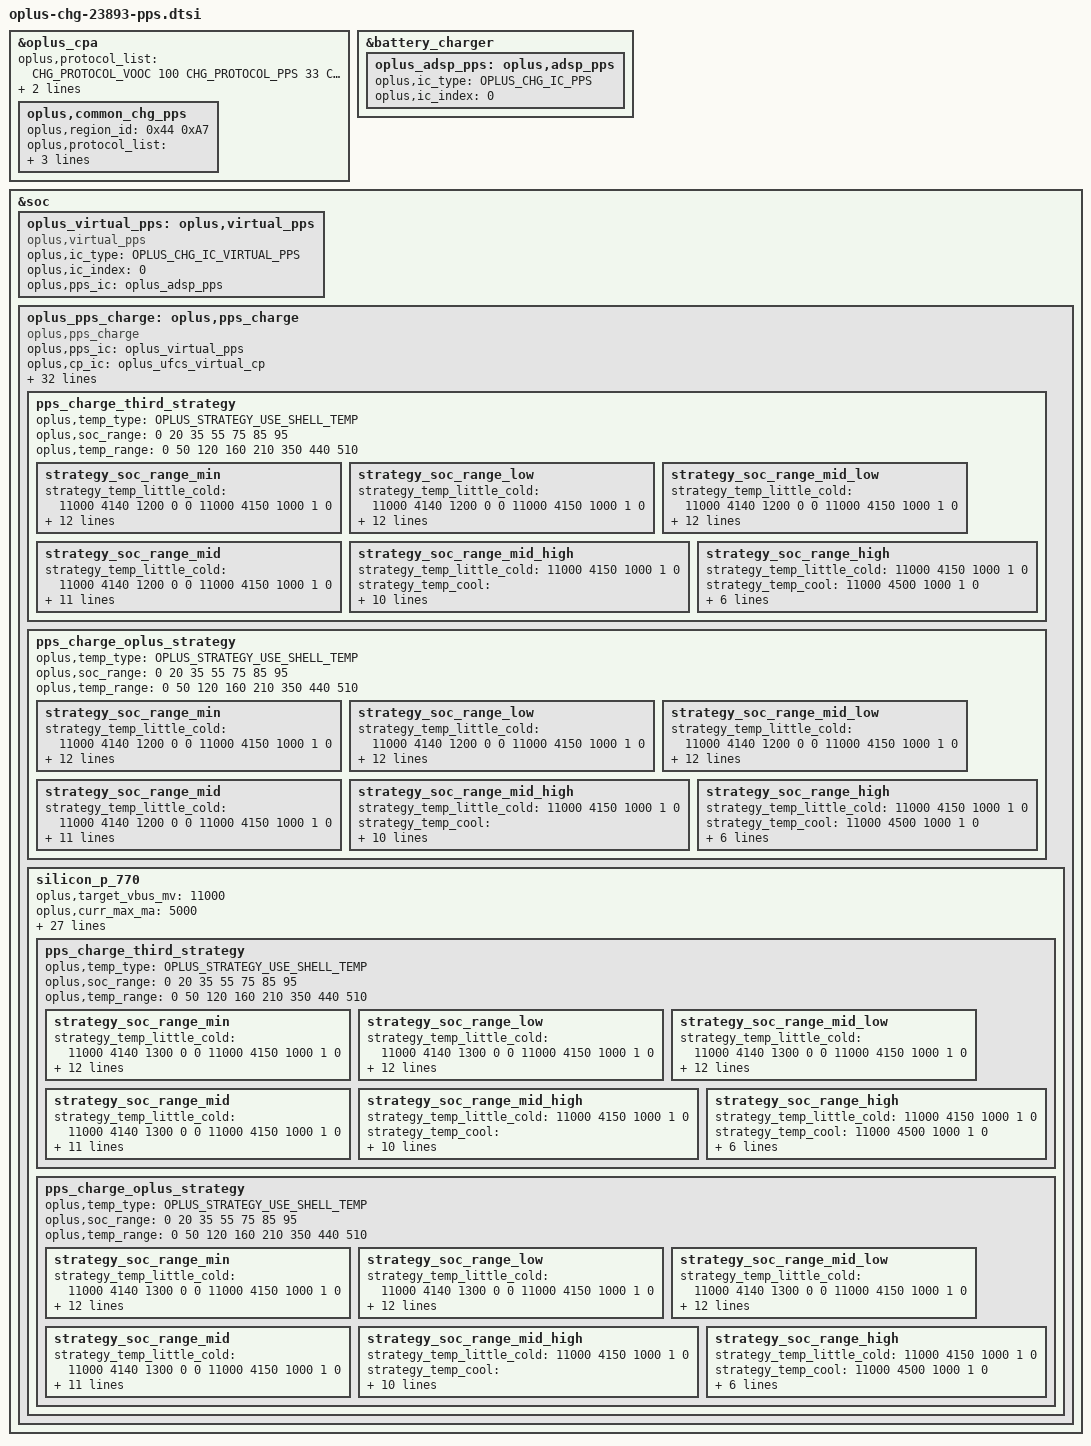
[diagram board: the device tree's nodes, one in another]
&oplus_cpa {
	oplus,protocol_list = <CHG_PROTOCOL_VOOC 100
				   CHG_PROTOCOL_PPS  33
				   CHG_PROTOCOL_PD   18
				   CHG_PROTOCOL_QC   18>;
	oplus,default_protocol_list = <CHG_PROTOCOL_PD
					   CHG_PROTOCOL_PPS
					   CHG_PROTOCOL_VOOC>;
	oplus,common_chg_pps {
		oplus,region_id = /bits/ 8 <0x44 0xA7>;
		oplus,protocol_list = <CHG_PROTOCOL_VOOC 100
				   CHG_PROTOCOL_PPS  55
				   CHG_PROTOCOL_PD   18
				   CHG_PROTOCOL_QC   18>;
		oplus,default_protocol_list = <CHG_PROTOCOL_PD
					   CHG_PROTOCOL_PPS
					   CHG_PROTOCOL_VOOC>;
	};
};
&battery_charger {
	oplus_adsp_pps: oplus,adsp_pps {
		oplus,ic_type = <OPLUS_CHG_IC_PPS>;
		oplus,ic_index = <0>;
	};
};
&soc {
	oplus_virtual_pps: oplus,virtual_pps {
		compatible = "oplus,virtual_pps";

		oplus,ic_type = <OPLUS_CHG_IC_VIRTUAL_PPS>;
		oplus,ic_index = <0>;
		oplus,pps_ic = <&oplus_adsp_pps>;
	};
	oplus_pps_charge: oplus,pps_charge {
		compatible = "oplus,pps_charge";
		oplus,pps_ic = <&oplus_virtual_pps>;
		oplus,cp_ic = <&oplus_ufcs_virtual_cp>;
		oplus,dpdm_switch_ic = <&oplus_adsp_dpdm_switch>;

		oplus,target_vbus_mv = <11000>;
		oplus,curr_max_ma = <5000>;

		oplus,pps_warm_allow_vol = <4000>;
		oplus,pps_warm_allow_soc = <55>;
		oplus,pps_strategy_normal_current = <5000>;
		oplus,pps_over_high_or_low_current = <3000>;
		oplus,pps_timeout_third = <13937>;
		oplus,pps_timeout_oplus = <13937>;
		oplus,pps_ibat_over_third = <6400>;
		oplus,pps_ibat_over_oplus = <6400>;
		oplus,pps_full_cool_sw_vbat = <4500>;
		oplus,pps_full_normal_sw_vbat = <4500>;
		oplus,pps_full_normal_hw_vbat = <4540>;
		oplus,pps_full_ffc_vbat = <4550>;
		oplus,pps_full_warm_vbat = <4130>;
		oplus,pps_full_cool_sw_vbat_third = <4500>;
		oplus,pps_full_normal_sw_vbat_third= <4500>;
		oplus,pps_full_normal_hw_vbat_third = <4540>;
		oplus,pps_current_change_timeout = <100>;
		oplus,pps_strategy_batt_high_temp = <410 420 430 400 410 420>;
		oplus,pps_strategy_high_current = <5000 5000 3000 5000 5000 5000>;
		oplus,pps_little_cool_high_temp = <210>;
		oplus,curve_strategy_name = "pps_ufcs_curve_v2";
		oplus,pps_charge_strategy_soc = <0 20 35 55 75 85 95>;
		oplus,pps_charge_strategy_temp = <0 50 120 160 350 440 510>;

		oplus,plc_strategy-data = <&pps_simple_strategy>;
		oplus,plc_strategy-names = "default";

		pps_charge_third_strategy {
			oplus,temp_type = <OPLUS_STRATEGY_USE_SHELL_TEMP>;
			oplus,soc_range = <0 20 35 55 75 85 95>;
			oplus,temp_range = <0 50 120 160 210 350 440 510>;

			strategy_soc_range_min {
				strategy_temp_little_cold =	<11000 4140 1200 0 0
								11000 4150 1000 1 0>;
				strategy_temp_cool =		<11000 4150 2000 0 0
								11000 4150 1500 0 0
								11000 4490 1200 0 0
								11000 4500 1000 1 0>;
				strategy_temp_little_cool =	<11000 4150 2600 0 0
								11000 4150 2500 0 0
								11000 4330 2000 0 0
								11000 4330 1500 0 0
								11000 4490 1200 0 0
								11000 4500 1000 1 0>;
				strategy_temp_little_cool_high = <11000 4200 5000 0 0
								11000 4200 4500 0 0
								11000 4200 4000 0 0
								11000 4330 3900 0 0
								11000 4330 3500 0 0
								11000 4490 3100 0 0
								11000 4490 3000 0 0
								11000 4490 2600 0 0
								11000 4490 2500 0 0
								11000 4490 2000 0 0
								11000 4490 1500 0 0
								11000 4500 1000 1 0>;
				strategy_temp_normal_low =	<11000 4480 5000 0 0
								11000 4480 4500 0 0
								11000 4480 4000 0 0
								11000 4490 3900 0 0
								11000 4490 3500 0 0
								11000 4490 3100 0 0
								11000 4490 3000 0 0
								11000 4490 2500 0 0
								11000 4490 2000 0 0
								11000 4490 1500 0 0
								11000 4500 1000 1 0>;
				strategy_temp_normal_high =	<11000 4465 5000 0 0
								11000 4465 4500 0 0
								11000 4465 4000 0 0
								11000 4465 3900 0 0
								11000 4465 3500 0 0
								11000 4465 3100 0 0
								11000 4465 3000 0 0
								11000 4465 2500 0 0
								11000 4465 2000 0 0
								11000 4465 1500 0 0
								11000 4475 1000 1 0>;
				strategy_temp_warm =		<11000 4120 1400 0 0
								11000 4130 1000 1 0>;
			};
			strategy_soc_range_low {
				strategy_temp_little_cold =	<11000 4140 1200 0 0
								11000 4150 1000 1 0>;
				strategy_temp_cool =		<11000 4150 2000 0 0
								11000 4150 1500 0 0
								11000 4490 1200 0 0
								11000 4500 1000 1 0>;
				strategy_temp_little_cool =	<11000 4150 2600 0 0
								11000 4150 2500 0 0
								11000 4330 2000 0 0
								11000 4330 1500 0 0
								11000 4490 1200 0 0
								11000 4500 1000 1 0>;
				strategy_temp_little_cool_high = <11000 4200 5000 0 0
								11000 4200 4500 0 0
								11000 4200 4000 0 0
								11000 4330 3900 0 0
								11000 4330 3500 0 0
								11000 4490 3100 0 0
								11000 4490 3000 0 0
								11000 4490 2600 0 0
								11000 4490 2500 0 0
								11000 4490 2000 0 0
								11000 4490 1500 0 0
								11000 4500 1000 1 0>;
				strategy_temp_normal_low =	<11000 4480 5000 0 0
								11000 4480 4500 0 0
								11000 4480 4000 0 0
								11000 4490 3900 0 0
								11000 4490 3500 0 0
								11000 4490 3100 0 0
								11000 4490 3000 0 0
								11000 4490 2500 0 0
								11000 4490 2000 0 0
								11000 4490 1500 0 0
								11000 4500 1000 1 0>;
				strategy_temp_normal_high =	<11000 4465 5000 0 0
								11000 4465 4500 0 0
								11000 4465 4000 0 0
								11000 4465 3900 0 0
								11000 4465 3500 0 0
								11000 4465 3100 0 0
								11000 4465 3000 0 0
								11000 4465 2500 0 0
								11000 4465 2000 0 0
								11000 4465 1500 0 0
								11000 4475 1000 1 0>;
				strategy_temp_warm =		<11000 4120 1400 0 0
								11000 4130 1000 1 0>;
			};
			strategy_soc_range_mid_low {
				strategy_temp_little_cold =	<11000 4140 1200 0 0
								11000 4150 1000 1 0>;
				strategy_temp_cool =		<11000 4150 2000 0 0
								11000 4150 1500 0 0
								11000 4490 1200 0 0
								11000 4500 1000 1 0>;
				strategy_temp_little_cool =	<11000 4150 2600 0 0
								11000 4150 2500 0 0
								11000 4330 2000 0 0
								11000 4330 1500 0 0
								11000 4490 1200 0 0
								11000 4500 1000 1 0>;
				strategy_temp_little_cool_high = <11000 4200 5000 0 0
								11000 4200 4500 0 0
								11000 4200 4000 0 0
								11000 4330 3900 0 0
								11000 4330 3500 0 0
								11000 4490 3100 0 0
								11000 4490 3000 0 0
								11000 4490 2600 0 0
								11000 4490 2500 0 0
								11000 4490 2000 0 0
								11000 4490 1500 0 0
								11000 4500 1000 1 0>;
				strategy_temp_normal_low =	<11000 4480 5000 0 0
								11000 4480 4500 0 0
								11000 4480 4000 0 0
								11000 4490 3900 0 0
								11000 4490 3500 0 0
								11000 4490 3100 0 0
								11000 4490 3000 0 0
								11000 4490 2500 0 0
								11000 4490 2000 0 0
								11000 4490 1500 0 0
								11000 4500 1000 1 0>;
				strategy_temp_normal_high =	<11000 4465 5000 0 0
								11000 4465 4500 0 0
								11000 4465 4000 0 0
								11000 4465 3900 0 0
								11000 4465 3500 0 0
								11000 4465 3100 0 0
								11000 4465 3000 0 0
								11000 4465 2500 0 0
								11000 4465 2000 0 0
								11000 4465 1500 0 0
								11000 4475 1000 1 0>;
				strategy_temp_warm =		<11000 4120 1400 0 0
								11000 4130 1000 1 0>;
			};
			strategy_soc_range_mid {
				strategy_temp_little_cold =	<11000 4140 1200 0 0
								11000 4150 1000 1 0>;
				strategy_temp_cool =		<11000 4150 2000 0 0
								11000 4150 1500 0 0
								11000 4490 1200 0 0
								11000 4500 1000 1 0>;
				strategy_temp_little_cool =	<11000 4150 2600 0 0
								11000 4150 2500 0 0
								11000 4330 2000 0 0
								11000 4330 1500 0 0
								11000 4490 1200 0 0
								11000 4500 1000 1 0>;
				strategy_temp_little_cool_high = <11000 4490 3000 0 0
								11000 4490 2600 0 0
								11000 4490 2500 0 0
								11000 4490 2000 0 0
								11000 4490 1500 0 0
								11000 4500 1000 1 0>;
				strategy_temp_normal_low =	<11000 4490 3500 0 0
								11000 4490 3100 0 0
								11000 4490 3000 0 0
								11000 4490 2500 0 0
								11000 4490 2000 0 0
								11000 4490 1500 0 0
								11000 4500 1000 1 0>;
				strategy_temp_normal_high =	<11000 4465 4000 0 0
								11000 4465 3900 0 0
								11000 4465 3500 0 0
								11000 4465 3100 0 0
								11000 4465 3000 0 0
								11000 4465 2500 0 0
								11000 4465 2000 0 0
								11000 4465 1500 0 0
								11000 4475 1000 1 0>;
				strategy_temp_warm =		<11000 4130 1000 1 0>;
			};
			strategy_soc_range_mid_high {
				strategy_temp_little_cold =	<11000 4150 1000 1 0>;
				strategy_temp_cool =		<11000 4150 1500 0 0
								11000 4490 1200 0 0
								11000 4500 1000 1 0>;
				strategy_temp_little_cool =	<11000 4330 2000 0 0
								11000 4330 1500 0 0
								11000 4490 1200 0 0
								11000 4500 1000 1 0>;
				strategy_temp_little_cool_high = <11000 4490 2000 0 0
								11000 4490 1500 0 0
								11000 4500 1000 1 0>;
				strategy_temp_normal_low =	<11000 4490 2500 0 0
								11000 4490 2000 0 0
								11000 4490 1500 0 0
								11000 4500 1000 1 0>;
				strategy_temp_normal_high =	<11000 4465 2500 0 0
								11000 4465 2000 0 0
								11000 4465 1500 0 0
								11000 4475 1000 1 0>;
				strategy_temp_warm =		<11000 4130 1000 1 0>;
			};
			strategy_soc_range_high {
				strategy_temp_little_cold =	<11000 4150 1000 1 0>;
				strategy_temp_cool =		<11000 4500 1000 1 0>;
				strategy_temp_little_cool =	<11000 4500 1000 1 0>;
				strategy_temp_little_cool_high = <11000 4500 1000 1 0>;
				strategy_temp_normal_low =	<11000 4500 1000 1 0>;
				strategy_temp_normal_high =	<11000 4475 1000 1 0>;
				strategy_temp_warm =		<11000 4130 1000 1 0>;
			};
		};

		pps_charge_oplus_strategy {
			oplus,temp_type = <OPLUS_STRATEGY_USE_SHELL_TEMP>;
			oplus,soc_range = <0 20 35 55 75 85 95>;
			oplus,temp_range = <0 50 120 160 210 350 440 510>;

			strategy_soc_range_min {
				strategy_temp_little_cold =	<11000 4140 1200 0 0
								11000 4150 1000 1 0>;
				strategy_temp_cool =		<11000 4150 2000 0 0
								11000 4150 1500 0 0
								11000 4490 1200 0 0
								11000 4500 1000 1 0>;
				strategy_temp_little_cool =	<11000 4150 2600 0 0
								11000 4150 2500 0 0
								11000 4330 2000 0 0
								11000 4330 1500 0 0
								11000 4490 1200 0 0
								11000 4500 1000 1 0>;
				strategy_temp_little_cool_high = <11000 4200 5000 0 0
								11000 4200 4500 0 0
								11000 4200 4000 0 0
								11000 4330 3900 0 0
								11000 4330 3500 0 0
								11000 4490 3100 0 0
								11000 4490 3000 0 0
								11000 4490 2600 0 0
								11000 4490 2500 0 0
								11000 4490 2000 0 0
								11000 4490 1500 0 0
								11000 4500 1000 1 0>;
				strategy_temp_normal_low =	<11000 4480 5000 0 0
								11000 4480 4500 0 0
								11000 4480 4000 0 0
								11000 4490 3900 0 0
								11000 4490 3500 0 0
								11000 4490 3100 0 0
								11000 4490 3000 0 0
								11000 4490 2500 0 0
								11000 4490 2000 0 0
								11000 4490 1500 0 0
								11000 4500 1000 1 0>;
				strategy_temp_normal_high =	<11000 4465 5000 0 0
								11000 4465 4500 0 0
								11000 4465 4000 0 0
								11000 4465 3900 0 0
								11000 4465 3500 0 0
								11000 4465 3100 0 0
								11000 4465 3000 0 0
								11000 4465 2500 0 0
								11000 4465 2000 0 0
								11000 4465 1500 0 0
								11000 4475 1000 1 0>;
				strategy_temp_warm =		<11000 4120 1400 0 0
								11000 4130 1000 1 0>;
			};
			strategy_soc_range_low {
				strategy_temp_little_cold =	<11000 4140 1200 0 0
								11000 4150 1000 1 0>;
				strategy_temp_cool =		<11000 4150 2000 0 0
								11000 4150 1500 0 0
								11000 4490 1200 0 0
								11000 4500 1000 1 0>;
				strategy_temp_little_cool =	<11000 4150 2600 0 0
								11000 4150 2500 0 0
								11000 4330 2000 0 0
								11000 4330 1500 0 0
								11000 4490 1200 0 0
								11000 4500 1000 1 0>;
				strategy_temp_little_cool_high = <11000 4200 5000 0 0
								11000 4200 4500 0 0
								11000 4200 4000 0 0
								11000 4330 3900 0 0
								11000 4330 3500 0 0
								11000 4490 3100 0 0
								11000 4490 3000 0 0
								11000 4490 2600 0 0
								11000 4490 2500 0 0
								11000 4490 2000 0 0
								11000 4490 1500 0 0
								11000 4500 1000 1 0>;
				strategy_temp_normal_low =	<11000 4480 5000 0 0
								11000 4480 4500 0 0
								11000 4480 4000 0 0
								11000 4490 3900 0 0
								11000 4490 3500 0 0
								11000 4490 3100 0 0
								11000 4490 3000 0 0
								11000 4490 2500 0 0
								11000 4490 2000 0 0
								11000 4490 1500 0 0
								11000 4500 1000 1 0>;
				strategy_temp_normal_high =	<11000 4465 5000 0 0
								11000 4465 4500 0 0
								11000 4465 4000 0 0
								11000 4465 3900 0 0
								11000 4465 3500 0 0
								11000 4465 3100 0 0
								11000 4465 3000 0 0
								11000 4465 2500 0 0
								11000 4465 2000 0 0
								11000 4465 1500 0 0
								11000 4475 1000 1 0>;
				strategy_temp_warm =		<11000 4120 1400 0 0
								11000 4130 1000 1 0>;
			};
			strategy_soc_range_mid_low {
				strategy_temp_little_cold =	<11000 4140 1200 0 0
								11000 4150 1000 1 0>;
				strategy_temp_cool =		<11000 4150 2000 0 0
								11000 4150 1500 0 0
								11000 4490 1200 0 0
								11000 4500 1000 1 0>;
				strategy_temp_little_cool =	<11000 4150 2600 0 0
								11000 4150 2500 0 0
								11000 4330 2000 0 0
								11000 4330 1500 0 0
								11000 4490 1200 0 0
								11000 4500 1000 1 0>;
				strategy_temp_little_cool_high = <11000 4200 5000 0 0
								11000 4200 4500 0 0
								11000 4200 4000 0 0
								11000 4330 3900 0 0
								11000 4330 3500 0 0
								11000 4490 3100 0 0
								11000 4490 3000 0 0
								11000 4490 2600 0 0
								11000 4490 2500 0 0
								11000 4490 2000 0 0
								11000 4490 1500 0 0
								11000 4500 1000 1 0>;
				strategy_temp_normal_low =	<11000 4480 5000 0 0
								11000 4480 4500 0 0
								11000 4480 4000 0 0
								11000 4490 3900 0 0
								11000 4490 3500 0 0
								11000 4490 3100 0 0
								11000 4490 3000 0 0
								11000 4490 2500 0 0
								11000 4490 2000 0 0
								11000 4490 1500 0 0
								11000 4500 1000 1 0>;
				strategy_temp_normal_high =	<11000 4465 5000 0 0
								11000 4465 4500 0 0
								11000 4465 4000 0 0
								11000 4465 3900 0 0
								11000 4465 3500 0 0
								11000 4465 3100 0 0
								11000 4465 3000 0 0
								11000 4465 2500 0 0
								11000 4465 2000 0 0
								11000 4465 1500 0 0
								11000 4475 1000 1 0>;
				strategy_temp_warm =		<11000 4120 1400 0 0
								11000 4130 1000 1 0>;
			};
			strategy_soc_range_mid {
				strategy_temp_little_cold =	<11000 4140 1200 0 0
								11000 4150 1000 1 0>;
				strategy_temp_cool =		<11000 4150 2000 0 0
								11000 4150 1500 0 0
								11000 4490 1200 0 0
								11000 4500 1000 1 0>;
				strategy_temp_little_cool =	<11000 4150 2600 0 0
								11000 4150 2500 0 0
								11000 4330 2000 0 0
								11000 4330 1500 0 0
								11000 4490 1200 0 0
								11000 4500 1000 1 0>;
				strategy_temp_little_cool_high = <11000 4490 3000 0 0
								11000 4490 2600 0 0
								11000 4490 2500 0 0
								11000 4490 2000 0 0
								11000 4490 1500 0 0
								11000 4500 1000 1 0>;
				strategy_temp_normal_low =	<11000 4490 3500 0 0
								11000 4490 3100 0 0
								11000 4490 3000 0 0
								11000 4490 2500 0 0
								11000 4490 2000 0 0
								11000 4490 1500 0 0
								11000 4500 1000 1 0>;
				strategy_temp_normal_high =	<11000 4465 4000 0 0
								11000 4465 3900 0 0
								11000 4465 3500 0 0
								11000 4465 3100 0 0
								11000 4465 3000 0 0
								11000 4465 2500 0 0
								11000 4465 2000 0 0
								11000 4465 1500 0 0
								11000 4475 1000 1 0>;
				strategy_temp_warm =		<11000 4130 1000 1 0>;
			};
			strategy_soc_range_mid_high {
				strategy_temp_little_cold =	<11000 4150 1000 1 0>;
				strategy_temp_cool =		<11000 4150 1500 0 0
								11000 4490 1200 0 0
								11000 4500 1000 1 0>;
				strategy_temp_little_cool =	<11000 4330 2000 0 0
								11000 4330 1500 0 0
								11000 4490 1200 0 0
								11000 4500 1000 1 0>;
				strategy_temp_little_cool_high = <11000 4490 2000 0 0
								11000 4490 1500 0 0
								11000 4500 1000 1 0>;
				strategy_temp_normal_low =	<11000 4490 2500 0 0
								11000 4490 2000 0 0
								11000 4490 1500 0 0
								11000 4500 1000 1 0>;
				strategy_temp_normal_high =	<11000 4465 2500 0 0
								11000 4465 2000 0 0
								11000 4465 1500 0 0
								11000 4475 1000 1 0>;
				strategy_temp_warm =		<11000 4130 1000 1 0>;
			};
			strategy_soc_range_high {
				strategy_temp_little_cold =	<11000 4150 1000 1 0>;
				strategy_temp_cool =		<11000 4500 1000 1 0>;
				strategy_temp_little_cool =	<11000 4500 1000 1 0>;
				strategy_temp_little_cool_high = <11000 4500 1000 1 0>;
				strategy_temp_normal_low =	<11000 4500 1000 1 0>;
				strategy_temp_normal_high =	<11000 4475 1000 1 0>;
				strategy_temp_warm =		<11000 4130 1000 1 0>;
			};
		};

		silicon_p_770 {
			oplus,target_vbus_mv = <11000>;
			oplus,curr_max_ma = <5000>;

			oplus,pps_warm_allow_vol = <4000>;
			oplus,pps_warm_allow_soc = <55>;
			oplus,pps_strategy_normal_current = <5000>;
			oplus,pps_over_high_or_low_current = <3000>;
			oplus,pps_timeout_third = <14425>;
			oplus,pps_timeout_oplus = <14425>;
			oplus,pps_ibat_over_third = <6400>;
			oplus,pps_ibat_over_oplus = <6400>;
			oplus,pps_full_cool_sw_vbat = <4500>;
			oplus,pps_full_normal_sw_vbat = <4500>;
			oplus,pps_full_normal_hw_vbat = <4540>;
			oplus,pps_full_ffc_vbat = <4550>;
			oplus,pps_full_warm_vbat = <4130>;
			oplus,pps_full_cool_sw_vbat_third = <4500>;
			oplus,pps_full_normal_sw_vbat_third= <4500>;
			oplus,pps_full_normal_hw_vbat_third = <4540>;
			oplus,pps_current_change_timeout = <100>;
			oplus,pps_strategy_batt_high_temp = <410 420 430 400 410 420>;
			oplus,pps_strategy_high_current = <5000 5000 3000 5000 5000 5000>;
			oplus,pps_little_cool_high_temp = <210>;
			oplus,curve_strategy_name = "pps_ufcs_curve_v2";
			oplus,pps_charge_strategy_soc = <0 20 35 55 75 85 95>;
			oplus,pps_charge_strategy_temp = <0 50 120 160 350 440 510>;

			pps_charge_third_strategy {
				oplus,temp_type = <OPLUS_STRATEGY_USE_SHELL_TEMP>;
				oplus,soc_range = <0 20 35 55 75 85 95>;
				oplus,temp_range = <0 50 120 160 210 350 440 510>;

				strategy_soc_range_min {
					strategy_temp_little_cold =	<11000 4140 1300 0 0
									11000 4150 1000 1 0>;
					strategy_temp_cool =		<11000 4150 2100 0 0
									11000 4150 2000 0 0
									11000 4150 1500 0 0
									11000 4490 1300 0 0
									11000 4500 1000 1 0>;
					strategy_temp_little_cool =	<11000 4150 2700 0 0
									11000 4150 2500 0 0
									11000 4330 2100 0 0
									11000 4330 2000 0 0
									11000 4330 1500 0 0
									11000 4490 1300 0 0
									11000 4500 1000 1 0>;
					strategy_temp_little_cool_high = <11000 4150 5000 0 0
									11000 4150 4500 0 0
									11000 4280 4000 0 0
									11000 4280 3500 0 0
									11000 4490 3200 0 0
									11000 4490 3000 0 0
									11000 4490 2700 0 0
									11000 4490 2500 0 0
									11000 4490 2000 0 0
									11000 4490 1500 0 0
									11000 4500 1000 1 0>;
					strategy_temp_normal_low =	<11000 4470 5000 0 0
									11000 4470 4500 0 0
									11000 4470 4000 0 0
									11000 4490 3800 0 0
									11000 4490 3500 0 0
									11000 4490 3000 0 0
									11000 4490 2500 0 0
									11000 4490 2000 0 0
									11000 4490 1500 0 0
									11000 4500 1000 1 0>;
					strategy_temp_normal_high =	<11000 4470 5000 0 0
									11000 4470 4500 0 0
									11000 4470 4000 0 0
									11000 4465 3800 0 0
									11000 4465 3500 0 0
									11000 4465 3000 0 0
									11000 4465 2500 0 0
									11000 4465 2000 0 0
									11000 4465 1500 0 0
									11000 4475 1000 1 0>;
					strategy_temp_warm =		<11000 4120 1500 0 0
									11000 4130 1000 1 0>;
				};
				strategy_soc_range_low {
					strategy_temp_little_cold =	<11000 4140 1300 0 0
									11000 4150 1000 1 0>;
					strategy_temp_cool =		<11000 4150 2100 0 0
									11000 4150 2000 0 0
									11000 4150 1500 0 0
									11000 4490 1300 0 0
									11000 4500 1000 1 0>;
					strategy_temp_little_cool =	<11000 4150 2700 0 0
									11000 4150 2500 0 0
									11000 4330 2100 0 0
									11000 4330 2000 0 0
									11000 4330 1500 0 0
									11000 4490 1300 0 0
									11000 4500 1000 1 0>;
					strategy_temp_little_cool_high = <11000 4150 5000 0 0
									11000 4150 4500 0 0
									11000 4280 4000 0 0
									11000 4280 3500 0 0
									11000 4490 3200 0 0
									11000 4490 3000 0 0
									11000 4490 2700 0 0
									11000 4490 2500 0 0
									11000 4490 2000 0 0
									11000 4490 1500 0 0
									11000 4500 1000 1 0>;
					strategy_temp_normal_low =	<11000 4470 5000 0 0
									11000 4470 4500 0 0
									11000 4470 4000 0 0
									11000 4490 3800 0 0
									11000 4490 3500 0 0
									11000 4490 3000 0 0
									11000 4490 2500 0 0
									11000 4490 2000 0 0
									11000 4490 1500 0 0
									11000 4500 1000 1 0>;
					strategy_temp_normal_high =	<11000 4470 5000 0 0
									11000 4470 4500 0 0
									11000 4470 4000 0 0
									11000 4465 3800 0 0
									11000 4465 3500 0 0
									11000 4465 3000 0 0
									11000 4465 2500 0 0
									11000 4465 2000 0 0
									11000 4465 1500 0 0
									11000 4475 1000 1 0>;
					strategy_temp_warm =		<11000 4120 1500 0 0
									11000 4130 1000 1 0>;
				};
				strategy_soc_range_mid_low {
					strategy_temp_little_cold =	<11000 4140 1300 0 0
									11000 4150 1000 1 0>;
					strategy_temp_cool =		<11000 4150 2100 0 0
									11000 4150 2000 0 0
									11000 4150 1500 0 0
									11000 4490 1300 0 0
									11000 4500 1000 1 0>;
					strategy_temp_little_cool =	<11000 4150 2700 0 0
									11000 4150 2500 0 0
									11000 4330 2100 0 0
									11000 4330 2000 0 0
									11000 4330 1500 0 0
									11000 4490 1300 0 0
									11000 4500 1000 1 0>;
					strategy_temp_little_cool_high = <11000 4150 5000 0 0
									11000 4150 4500 0 0
									11000 4280 4000 0 0
									11000 4280 3500 0 0
									11000 4490 3200 0 0
									11000 4490 3000 0 0
									11000 4490 2700 0 0
									11000 4490 2500 0 0
									11000 4490 2000 0 0
									11000 4490 1500 0 0
									11000 4500 1000 1 0>;
					strategy_temp_normal_low =	<11000 4470 5000 0 0
									11000 4470 4500 0 0
									11000 4470 4000 0 0
									11000 4490 3800 0 0
									11000 4490 3500 0 0
									11000 4490 3000 0 0
									11000 4490 2500 0 0
									11000 4490 2000 0 0
									11000 4490 1500 0 0
									11000 4500 1000 1 0>;
					strategy_temp_normal_high =	<11000 4470 5000 0 0
									11000 4470 4500 0 0
									11000 4470 4000 0 0
									11000 4465 3800 0 0
									11000 4465 3500 0 0
									11000 4465 3000 0 0
									11000 4465 2500 0 0
									11000 4465 2000 0 0
									11000 4465 1500 0 0
									11000 4475 1000 1 0>;
					strategy_temp_warm =		<11000 4120 1500 0 0
									11000 4130 1000 1 0>;
				};
				strategy_soc_range_mid {
					strategy_temp_little_cold =	<11000 4140 1300 0 0
									11000 4150 1000 1 0>;
					strategy_temp_cool =		<11000 4150 2000 0 0
									11000 4150 1500 0 0
									11000 4490 1300 0 0
									11000 4500 1000 1 0>;
					strategy_temp_little_cool =	<11000 4150 2700 0 0
									11000 4150 2500 0 0
									11000 4330 2100 0 0
									11000 4330 2000 0 0
									11000 4330 1500 0 0
									11000 4490 1300 0 0
									11000 4500 1000 1 0>;
					strategy_temp_little_cool_high = <11000 4490 3000 0 0
									11000 4490 2700 0 0
									11000 4490 2500 0 0
									11000 4490 2000 0 0
									11000 4490 1500 0 0
									11000 4500 1000 1 0>;
					strategy_temp_normal_low =	<11000 4490 3500 0 0
									11000 4490 3000 0 0
									11000 4490 2500 0 0
									11000 4490 2000 0 0
									11000 4490 1500 0 0
									11000 4500 1000 1 0>;
					strategy_temp_normal_high =	<11000 4470 4000 0 0
									11000 4465 3800 0 0
									11000 4465 3500 0 0
									11000 4465 3000 0 0
									11000 4465 2500 0 0
									11000 4465 2000 0 0
									11000 4465 1500 0 0
									11000 4475 1000 1 0>;
					strategy_temp_warm =		<11000 4130 1000 1 0>;
				};
				strategy_soc_range_mid_high {
					strategy_temp_little_cold =	<11000 4150 1000 1 0>;
					strategy_temp_cool =		<11000 4150 1500 0 0
									11000 4490 1300 0 0
									11000 4500 1000 1 0>;
					strategy_temp_little_cool =	<11000 4330 2000 0 0
									11000 4330 1500 0 0
									11000 4490 1300 0 0
									11000 4500 1000 1 0>;
					strategy_temp_little_cool_high = <11000 4490 2000 0 0
									11000 4490 1500 0 0
									11000 4500 1000 1 0>;
					strategy_temp_normal_low =	<11000 4490 2500 0 0
									11000 4490 2000 0 0
									11000 4490 1500 0 0
									11000 4500 1000 1 0>;
					strategy_temp_normal_high =	<11000 4465 2500 0 0
									11000 4465 2000 0 0
									11000 4465 1500 0 0
									11000 4475 1000 1 0>;
					strategy_temp_warm =		<11000 4130 1000 1 0>;
				};
				strategy_soc_range_high {
					strategy_temp_little_cold =	<11000 4150 1000 1 0>;
					strategy_temp_cool =		<11000 4500 1000 1 0>;
					strategy_temp_little_cool =	<11000 4500 1000 1 0>;
					strategy_temp_little_cool_high = <11000 4500 1000 1 0>;
					strategy_temp_normal_low =	<11000 4500 1000 1 0>;
					strategy_temp_normal_high =	<11000 4475 1000 1 0>;
					strategy_temp_warm =		<11000 4130 1000 1 0>;
				};
			};

			pps_charge_oplus_strategy {
				oplus,temp_type = <OPLUS_STRATEGY_USE_SHELL_TEMP>;
				oplus,soc_range = <0 20 35 55 75 85 95>;
				oplus,temp_range = <0 50 120 160 210 350 440 510>;

				strategy_soc_range_min {
					strategy_temp_little_cold =	<11000 4140 1300 0 0
									11000 4150 1000 1 0>;
					strategy_temp_cool =		<11000 4150 2100 0 0
									11000 4150 2000 0 0
									11000 4150 1500 0 0
									11000 4490 1300 0 0
									11000 4500 1000 1 0>;
					strategy_temp_little_cool =	<11000 4150 2700 0 0
									11000 4150 2500 0 0
									11000 4330 2100 0 0
									11000 4330 2000 0 0
									11000 4330 1500 0 0
									11000 4490 1300 0 0
									11000 4500 1000 1 0>;
					strategy_temp_little_cool_high = <11000 4150 5000 0 0
									11000 4150 4500 0 0
									11000 4280 4000 0 0
									11000 4280 3500 0 0
									11000 4490 3200 0 0
									11000 4490 3000 0 0
									11000 4490 2700 0 0
									11000 4490 2500 0 0
									11000 4490 2000 0 0
									11000 4490 1500 0 0
									11000 4500 1000 1 0>;
					strategy_temp_normal_low =	<11000 4470 5000 0 0
									11000 4470 4500 0 0
									11000 4470 4000 0 0
									11000 4490 3800 0 0
									11000 4490 3500 0 0
									11000 4490 3000 0 0
									11000 4490 2500 0 0
									11000 4490 2000 0 0
									11000 4490 1500 0 0
									11000 4500 1000 1 0>;
					strategy_temp_normal_high =	<11000 4470 5000 0 0
									11000 4470 4500 0 0
									11000 4470 4000 0 0
									11000 4465 3800 0 0
									11000 4465 3500 0 0
									11000 4465 3000 0 0
									11000 4465 2500 0 0
									11000 4465 2000 0 0
									11000 4465 1500 0 0
									11000 4475 1000 1 0>;
					strategy_temp_warm =		<11000 4120 1500 0 0
									11000 4130 1000 1 0>;
				};
				strategy_soc_range_low {
					strategy_temp_little_cold =	<11000 4140 1300 0 0
									11000 4150 1000 1 0>;
					strategy_temp_cool =		<11000 4150 2100 0 0
									11000 4150 2000 0 0
									11000 4150 1500 0 0
									11000 4490 1300 0 0
									11000 4500 1000 1 0>;
					strategy_temp_little_cool =	<11000 4150 2700 0 0
									11000 4150 2500 0 0
									11000 4330 2100 0 0
									11000 4330 2000 0 0
									11000 4330 1500 0 0
									11000 4490 1300 0 0
									11000 4500 1000 1 0>;
					strategy_temp_little_cool_high = <11000 4150 5000 0 0
									11000 4150 4500 0 0
									11000 4280 4000 0 0
									11000 4280 3500 0 0
									11000 4490 3200 0 0
									11000 4490 3000 0 0
									11000 4490 2700 0 0
									11000 4490 2500 0 0
									11000 4490 2000 0 0
									11000 4490 1500 0 0
									11000 4500 1000 1 0>;
					strategy_temp_normal_low =	<11000 4470 5000 0 0
									11000 4470 4500 0 0
									11000 4470 4000 0 0
									11000 4490 3800 0 0
									11000 4490 3500 0 0
									11000 4490 3000 0 0
									11000 4490 2500 0 0
									11000 4490 2000 0 0
									11000 4490 1500 0 0
									11000 4500 1000 1 0>;
					strategy_temp_normal_high =	<11000 4470 5000 0 0
									11000 4470 4500 0 0
									11000 4470 4000 0 0
									11000 4465 3800 0 0
									11000 4465 3500 0 0
									11000 4465 3000 0 0
									11000 4465 2500 0 0
									11000 4465 2000 0 0
									11000 4465 1500 0 0
									11000 4475 1000 1 0>;
					strategy_temp_warm =		<11000 4120 1500 0 0
									11000 4130 1000 1 0>;
				};
				strategy_soc_range_mid_low {
					strategy_temp_little_cold =	<11000 4140 1300 0 0
									11000 4150 1000 1 0>;
					strategy_temp_cool =		<11000 4150 2100 0 0
									11000 4150 2000 0 0
									11000 4150 1500 0 0
									11000 4490 1300 0 0
									11000 4500 1000 1 0>;
					strategy_temp_little_cool =	<11000 4150 2700 0 0
									11000 4150 2500 0 0
									11000 4330 2100 0 0
									11000 4330 2000 0 0
									11000 4330 1500 0 0
									11000 4490 1300 0 0
									11000 4500 1000 1 0>;
					strategy_temp_little_cool_high = <11000 4150 5000 0 0
									11000 4150 4500 0 0
									11000 4280 4000 0 0
									11000 4280 3500 0 0
									11000 4490 3200 0 0
									11000 4490 3000 0 0
									11000 4490 2700 0 0
									11000 4490 2500 0 0
									11000 4490 2000 0 0
									11000 4490 1500 0 0
									11000 4500 1000 1 0>;
					strategy_temp_normal_low =	<11000 4470 5000 0 0
									11000 4470 4500 0 0
									11000 4470 4000 0 0
									11000 4490 3800 0 0
									11000 4490 3500 0 0
									11000 4490 3000 0 0
									11000 4490 2500 0 0
									11000 4490 2000 0 0
									11000 4490 1500 0 0
									11000 4500 1000 1 0>;
					strategy_temp_normal_high =	<11000 4470 5000 0 0
									11000 4470 4500 0 0
									11000 4470 4000 0 0
									11000 4465 3800 0 0
									11000 4465 3500 0 0
									11000 4465 3000 0 0
									11000 4465 2500 0 0
									11000 4465 2000 0 0
									11000 4465 1500 0 0
									11000 4475 1000 1 0>;
					strategy_temp_warm =		<11000 4120 1500 0 0
									11000 4130 1000 1 0>;
				};
				strategy_soc_range_mid {
					strategy_temp_little_cold =	<11000 4140 1300 0 0
									11000 4150 1000 1 0>;
					strategy_temp_cool =		<11000 4150 2000 0 0
									11000 4150 1500 0 0
									11000 4490 1300 0 0
									11000 4500 1000 1 0>;
					strategy_temp_little_cool =	<11000 4150 2700 0 0
									11000 4150 2500 0 0
									11000 4330 2100 0 0
									11000 4330 2000 0 0
									11000 4330 1500 0 0
									11000 4490 1300 0 0
									11000 4500 1000 1 0>;
					strategy_temp_little_cool_high = <11000 4490 3000 0 0
									11000 4490 2700 0 0
									11000 4490 2500 0 0
									11000 4490 2000 0 0
									11000 4490 1500 0 0
									11000 4500 1000 1 0>;
					strategy_temp_normal_low =	<11000 4490 3500 0 0
									11000 4490 3000 0 0
									11000 4490 2500 0 0
									11000 4490 2000 0 0
									11000 4490 1500 0 0
									11000 4500 1000 1 0>;
					strategy_temp_normal_high =	<11000 4470 4000 0 0
									11000 4465 3800 0 0
									11000 4465 3500 0 0
									11000 4465 3000 0 0
									11000 4465 2500 0 0
									11000 4465 2000 0 0
									11000 4465 1500 0 0
									11000 4475 1000 1 0>;
					strategy_temp_warm =		<11000 4130 1000 1 0>;
				};
				strategy_soc_range_mid_high {
					strategy_temp_little_cold =	<11000 4150 1000 1 0>;
					strategy_temp_cool =		<11000 4150 1500 0 0
									11000 4490 1300 0 0
									11000 4500 1000 1 0>;
					strategy_temp_little_cool =	<11000 4330 2000 0 0
									11000 4330 1500 0 0
									11000 4490 1300 0 0
									11000 4500 1000 1 0>;
					strategy_temp_little_cool_high = <11000 4490 2000 0 0
									11000 4490 1500 0 0
									11000 4500 1000 1 0>;
					strategy_temp_normal_low =	<11000 4490 2500 0 0
									11000 4490 2000 0 0
									11000 4490 1500 0 0
									11000 4500 1000 1 0>;
					strategy_temp_normal_high =	<11000 4465 2500 0 0
									11000 4465 2000 0 0
									11000 4465 1500 0 0
									11000 4475 1000 1 0>;
					strategy_temp_warm =		<11000 4130 1000 1 0>;
				};
				strategy_soc_range_high {
					strategy_temp_little_cold =	<11000 4150 1000 1 0>;
					strategy_temp_cool =		<11000 4500 1000 1 0>;
					strategy_temp_little_cool =	<11000 4500 1000 1 0>;
					strategy_temp_little_cool_high = <11000 4500 1000 1 0>;
					strategy_temp_normal_low =	<11000 4500 1000 1 0>;
					strategy_temp_normal_high =	<11000 4475 1000 1 0>;
					strategy_temp_warm =		<11000 4130 1000 1 0>;
				};
			};
		};
	};
};
